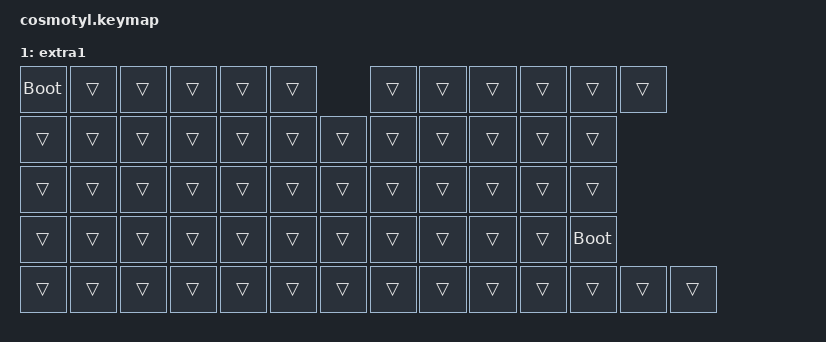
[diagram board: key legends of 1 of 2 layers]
#include <behaviors.dtsi>
#include <dt-bindings/zmk/keys.h>
#include <dt-bindings/zmk/bt.h>
#include <dt-bindings/zmk/rgb.h>

/ {
    keymap {
        compatible = "zmk,keymap";

        default_layer {
            bindings = <&kp SPACE &kp N1 &kp N2 &kp N3 &kp N4 &kp N5 &kp N6 &kp N7 &kp N8 &kp N9 &kp N0 &kp SPACE &kp SPACE &kp Q &kp W &kp E &kp R &kp T &kp Y &kp U &kp I &kp O &kp P &kp SPACE &kp SPACE &kp A &kp S &kp D &kp F &kp G &kp H &kp J &kp K &kp L &kp SEMI &kp SPACE &kp SPACE &kp Z &kp X &kp C &kp V &kp B &kp N &kp M &kp COMMA &kp DOT &kp FSLH &studio_unlock &kp RBKT &kp LBKT &kp LBKT &kp RBKT &kp SPACE &mo 1 &kp SPACE &kp SPACE &kp SPACE &mo 1 &kp SPACE &kp SPACE>;
        };

        extra1 {
            bindings = <
                &bootloader &trans &trans &trans &trans &trans &trans &trans &trans &trans &trans &trans
                &trans &trans &trans &trans &trans &trans &trans &trans &trans &trans &trans &trans
                &trans &trans &trans &trans &trans &trans &trans &trans &trans &trans &trans &trans
                &trans &trans &trans &trans &trans &trans &trans &trans &trans &trans &trans &bootloader
                &trans &trans &trans &trans &trans &trans &trans &trans &trans &trans &trans &trans &trans &trans
            >;
        };

        extra2 {
            status = "reserved";
        };

        extra3 {
            status = "reserved";
        };
    };
};
